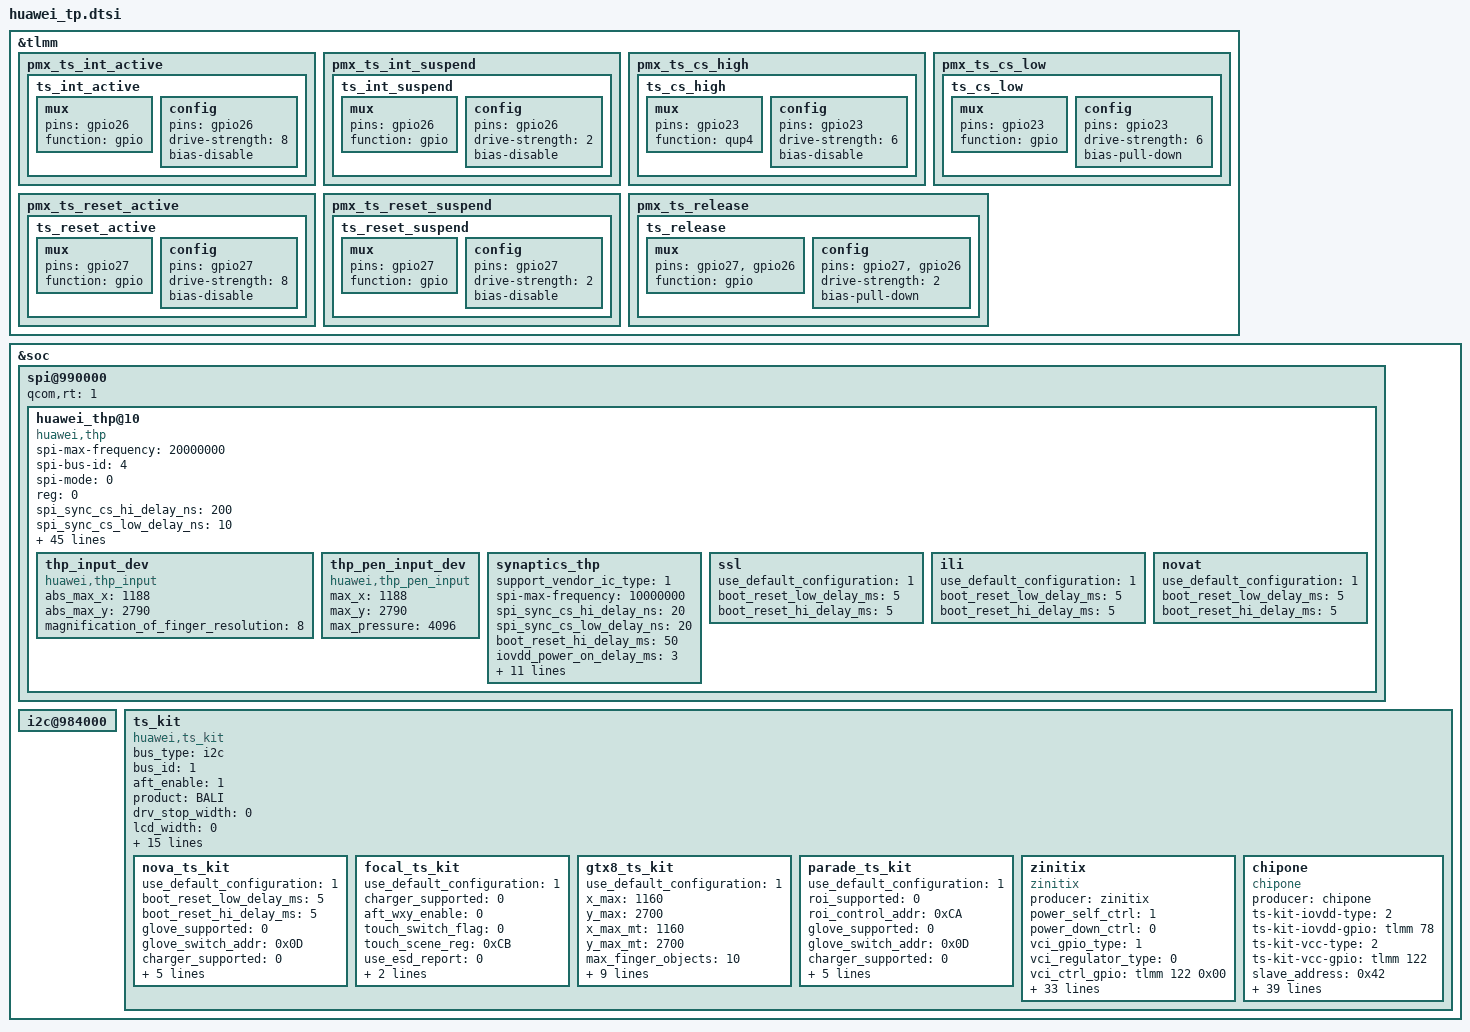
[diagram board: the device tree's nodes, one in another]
/* touch panel config */
&tlmm {
	pmx_ts_int_active {
		ts_int_active: ts_int_active {
			mux {
				pins = "gpio26";
				function = "gpio";
			};

			config {
				pins = "gpio26";
				drive-strength = <8>;
				bias-disable;
			};
		};
	};

	pmx_ts_int_suspend {
		ts_int_suspend: ts_int_suspend {
			mux {
				pins = "gpio26";
				function = "gpio";
			};

			config {
				pins = "gpio26";
				drive-strength = <2>;
				bias-disable;
			};
		};
	};

	pmx_ts_cs_high {
		ts_cs_high: ts_cs_high {
			mux {
				pins = "gpio23";
				function = "qup4";
			};

			config {
				pins = "gpio23";
				drive-strength = <6>;
				bias-disable;
			};
		};
	};

	pmx_ts_cs_low {
		ts_cs_low: ts_cs_low {
			mux {
				pins = "gpio23";
				function = "gpio";
			};

			config {
				pins = "gpio23";
				drive-strength = <6>;
				bias-pull-down;
			};
		};
	};

	pmx_ts_reset_active {
		ts_reset_active: ts_reset_active {
			mux {
				pins = "gpio27";
				function = "gpio";
			};

			config {
				pins = "gpio27";
				drive-strength = <8>;
				bias-disable;
			};
		};
	};

	pmx_ts_reset_suspend {
		ts_reset_suspend: ts_reset_suspend {
			mux {
				pins = "gpio27";
				function = "gpio";
			};

			config {
				pins = "gpio27";
				drive-strength = <2>;
				bias-disable;
			};
		};
	};

	pmx_ts_release {
		ts_release: ts_release {
			mux {
				pins = "gpio27", "gpio26";
				function = "gpio";
			};

			config {
				pins = "gpio27", "gpio26";
				drive-strength = <2>;
				bias-pull-down;
			};
		};
	};
};

&soc {
	spi@990000 {
		status = "ok";
		#address-cells = <1>;
		#size-cells = <0>;
		qcom,rt = <1>;
		huawei_thp@10 {
			compatible = "huawei,thp";
			status = "ok";
			/* SPI Config */
			spi-max-frequency = <20000000>;
			spi-bus-id = <4>;
			spi-mode = <0>;
			reg = <0>;
			spi_sync_cs_hi_delay_ns = <200>;
			spi_sync_cs_low_delay_ns = <10>;

			/* Power Config */
			thp-vcc-type = <1>;
			thp-vcc-supply = <&L3C>;
			thp-vcc-value = <3296000>;
			thp-iovdd-type = <2>;
			thp-iovdd-gpio = <&tlmm 30 0x00>;

			/* Timing */
			boot_reset_hi_delay_ms = <1>;
			boot_reset_low_delay_ms = <0>;
			boot_reset_after_delay_ms = <0>;
			resume_reset_after_delay_ms = <1>;
			suspend_reset_after_delay_ms = <1>;
			use_mdelay = <1>;

			/* GPIO Config */
			irq_flag = <0x00000002>;
			interrupt-parent = <&tlmm>;
			interrupts = <26 0>;
			rst_gpio = <&tlmm 27 0x00>;
			irq_gpio = <&tlmm 26 0x00>;
			cs_gpio = <&tlmm 23 0x00>;
			pinctrl-names = "default", "idle", "state_cs_output1", "state_cs_output0";
			pinctrl-0 = <&ts_int_active &ts_reset_active>;
			pinctrl-1 = <&ts_int_suspend &ts_reset_suspend>;
			pinctrl-2 = <&ts_cs_high>;
			pinctrl-3 = <&ts_cs_low>;
			support_no_cs_for_qcom = <1>;
			support_control_cs_off = <1>;

			/* Feature Config */
			support_pinctrl = <1>;
			pinctrl_init_enable = <1>;
			pt_station_test = <0>;
			support_gesture_mode = <1>;
			hide_product_info_en = <1>;
			supported_func_indicater = <0x00>;
			fast_booting_solution = <1>;
			support_fingerprint_switch = <0>;
			pen_supported = <0>;
			pen_mt_enable_flag = <0>;
			project_in_tp = <1>;
			aod_display_support = <1>;
			support_factory_mode_extra_cmd = <2>;
			need_notify_to_roi_algo = <1>;
			use_ap_gesture = <1>;
			use_thp_queue = <1>;
			supported_charger = <1>;
			multi_panel_index = <0>;
			support_screen_switch = <1>;
			support_input_location = <1>;
			avoid_low_level_irq_storm = <1>;
			need_enable_irq_wake = <1>;
			thp_input_dev {
				compatible = "huawei,thp_input";
				abs_max_x = <1188>;
				abs_max_y = <2790>;
				magnification_of_finger_resolution = <8>;
			};
			thp_pen_input_dev {
				compatible = "huawei,thp_pen_input";
				max_x = <1188>;
				max_y = <2790>;
				max_pressure = <4096>;
			};
			synaptics_thp {
				support_vendor_ic_type = <1>;
				spi-max-frequency = <10000000>;
				spi_sync_cs_hi_delay_ns = <20>;
				spi_sync_cs_low_delay_ns = <20>;
				boot_reset_hi_delay_ms = <50>;
				iovdd_power_on_delay_ms = <3>;
				self_control_power = <1>;
				need_huge_memory_in_spi = <1>;
				/* IRQF_TRIGGER_LOW 0x00000008 */
				irq_flag = <0x00000008>;
				support_get_frame_read_once = <1>;
				support_fingerprint_switch = <0>;
				aod_display_support = <1>;
				use_aod_power_ctrl_notify = <1>;
				suspend_delayms_early_to_before = <150>;
				suspend_delayms_before_to_later = <15>;
				resume_delayms_early_to_later = <50>;
				need_enable_irq_wake = <1>;
			};
			ssl {
				use_default_configuration = <1>;
				boot_reset_low_delay_ms = <5>;
				boot_reset_hi_delay_ms = <5>;
			};
			ili {
				use_default_configuration = <1>;
				boot_reset_low_delay_ms = <5>;
				boot_reset_hi_delay_ms = <5>;
			};
			novat {
				use_default_configuration = <1>;
				boot_reset_low_delay_ms = <5>;
				boot_reset_hi_delay_ms = <5>;
			};
		};
	};

	i2c@984000 {
		status = "ok";
		#address-cells = <1>;
		#size-cells = <0>;
	};

	ts_kit {
		status = "ok";
		compatible = "huawei,ts_kit";
		bus_type = "i2c";
		bus_id = <1>;
		aft_enable = <1>;
		product = "BALI";
		drv_stop_width = <0>;
		lcd_width = <0>;
		lcd_height = <0>;
		need_i2c_hwlock = <0>;
		interrupt-parent = <&tlmm>;
		interrupts = <36 0>;
		reset_gpio = <&tlmm 37 0x00>;
		irq_gpio = <&tlmm 36 0x00>;
		register_charger_notifier = <1>;
		multi_panel_index = <1>;
		support_input_location = <1>;
		support_factory_mode_extra_cmd = <1>;
		setting_multi_gesture_mode = <1>;
		aod_display_support=<1>;
		hide_plain_id = <1>;
		fp_tp_enable = <0>;
		need_enable_irq_wake = <1>;
		nova_ts_kit {
			use_default_configuration = <1>;
			boot_reset_low_delay_ms = <5>;
			boot_reset_hi_delay_ms = <5>;
			glove_supported = <0>;
			glove_switch_addr = <0x0D>;
			charger_supported = <0>;
			aft_wxy_enable = <0>;
			max_finger_objects = <10>;
			rawdata_newformatflag = <1>;
			roi_supported = <0>;
			roi_control_addr = <0xCA>;
		};
		focal_ts_kit {
			use_default_configuration = <1>;
			charger_supported = <0>;
			aft_wxy_enable = <0>;
			touch_switch_flag = <0>;
			touch_scene_reg = <0xCB>;
			use_esd_report = <0>;
			boot_reset_low_delay_ms = <5>;
			boot_reset_hi_delay_ms = <5>;
		};
		gtx8_ts_kit {
			use_default_configuration = <1>;
			x_max = <1160>;
			y_max = <2700>;
			x_max_mt = <1160>;
			y_max_mt = <2700>;
			max_finger_objects = <10>;
			rawdata_newformatflag = <1>;
			roi_supported = <0>;
			roi_control_addr = <0xCA>;
			glove_supported = <0>;
			glove_switch_addr = <0x0D>;
			charger_supported = <0>;
			aft_wxy_enable = <0>;
			boot_reset_low_delay_ms = <5>;
			boot_reset_hi_delay_ms = <5>;
		};
		parade_ts_kit {
			use_default_configuration = <1>;
			roi_supported = <0>;
			roi_control_addr = <0xCA>;
			glove_supported = <0>;
			glove_switch_addr = <0x0D>;
			charger_supported = <0>;
			aft_wxy_enable = <0>;
			touch_switch_flag = <0>; // 1-doze 2-game 4-scene
			touch_scene_reg = <0xCB>;
			use_esd_report = <0>;
			support_vendor_ic_type = <1>;
		};
		zinitix {
			status = "ok";
			compatible = "zinitix";
			producer = "zinitix";
			power_self_ctrl = <1>;
			power_down_ctrl = <0>;
			vci_gpio_type = <1>;
			vci_regulator_type = <0>;
			vci_ctrl_gpio = <&tlmm 122 0x00>;
			//zts-vdd-supply = <&ldo24>;
			vci_value = <3000000>;

			vddio_gpio_type = <1>;
			vddio_regulator_type = <0>;
			vddio_value = <1800000>;
			vddio_ctrl_gpio = <&tlmm 78 0x00>;
			glove_supported = <0>;

			slave_address = <0x20>;
			irq_config = <3>;
			algo_id = <1>;
			ic_type = <0>;
			pinctrl-names = "default", "idle";
			pinctrl-0 = <&qupv3_se1_i2c_active>;
			pinctrl-1 = <&qupv3_se1_i2c_sleep>;
			x_max = <340>;
			y_max = <340>;
			x_max_mt = <340>;
			y_max_mt = <340>;
			boot-hw-reset-timing = <5 5 50>;
			max_finger_objects = <2>;
			rawdata_newformatflag = <1>;
			roi_supported = <0>;
			roi_control_addr = <0>;
			glove_switch_addr = <0>;
			holster_supported = <0>;
			charger_supported = <0>;
			aft_wxy_enable = <0>;
			touch_switch_flag = <0>; // 1-doze 2-game 4-scene
			use_esd_report = <0>;
			support_vendor_ic_type = <0>;
			need_notify_to_roi_algo = <1>;
			defaut_vendor_name = "multi_touch_sxx_sxx";
			support_notice_aft_gesture_mode = <1>;
			need_wd_check_status = <1>;
			check_status_watchdog_timeout = <3000>;
		};
		chipone {
			status = "ok";
			compatible = "chipone";
			producer = "chipone";
			ts-kit-iovdd-type = <2>; /* 0-unused 1-ldo 2-gpio */
			ts-kit-iovdd-gpio = <&tlmm 78 0x00>;

			ts-kit-vcc-type = <2>; /* 0-unused 1-ldo 2-gpio 3-pmic */
			ts-kit-vcc-gpio = <&tlmm 122 0x00>;
			// ts-kit-vcc-value = <3000000>;

			slave_address = <0x42>;
			irq_config = <3>;
			ic_type = <0x8918>;
			use_pinctrl = <0>;
			x_max = <340>;
			y_max = <340>;
			x_max_mt = <340>;
			y_max_mt = <340>;
			boot-hw-reset-timing = /bits/ 8 <2 5 40>;
			resume-hw-reset-timing = /bits/ 8 <2 5 40>;
			max_finger_objects = <2>;
			rawdata_newformatflag = <1>;
			roi_supported = <0>;
			roi_control_addr = <0>;
			glove_supported = <0>;
			glove_switch_addr = <0>;
			holster_supported = <0>;
			charger_supported = <1>;
			aft_wxy_enable = <0>;
			touch_switch_flag = <0>; // 1-doze 2-game 4-scene
			use_esd_report = <0>;
			support_vendor_ic_type = <0>;
			need_notify_to_roi_algo = <1>;
			defaut_vendor_name = "multi_touch_sxx_sxx";
			support_notice_aft_gesture_mode = <1>;
			use-huawei-charger-detect = <1>;
			use-pinctrl = <0>;
			is_ic_rawdata_proc_printf = <1>;
			hide_fw_name = <0>;
			need_wd_check_status = <1>;
			check_status_watchdog_timeout = <3000>;
			huawei,csvfile_use_product_system = <0>;
			huawei,test_capacitance_via_csvfile = <1>;
			dump-factory-test-data-to-console = <1>;
			dump-factory-test-data-to-buffer = <1>;
			dump-factory-test-data-to-file = <0>;
			print-factory-test-data-only-fail = <0>;
			tp_test_type = "Normalize_type:judge_last_result";
			factory-test-data-directory = "/sdcard/chipone/test/";
		};
	};
};
